# WS63 register map
File version: 1.0
CPU: other r0p0, little endian, MPU, FPU, 3 interrupt priority bits
Registers are 32-bit, read-write, reset 0x0 unless marked. A register's access mark holds for its fields unless they carry their own. Offsets are from the block's base; [hi:lo] are bit positions; {n}, {i} and the like mark numbered series.

## EFUSE — eFuse controller (OTP, v151)
Base 0x44008000
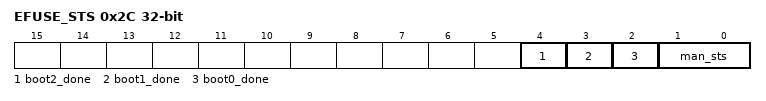
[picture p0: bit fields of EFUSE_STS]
0x2C EFUSE_STS — eFuse boot-done status register (base+0x2C). Read-only.
  [4] boot2_done ro — Boot2 done flag
  [3] boot1_done ro — Boot1 done flag
  [2] boot0_done ro — Boot0 done flag
  [1:0] man_sts ro — Manufacturing status
0x30 EFUSE_CTL_DATA — eFuse mode-select register (base+0x30). Write the 16-bit magic to arm an access: 0xA5A5 = program (write) mode, 0x5A5A = read mode.
  [15:0] efuse_wr_rd — Mode-select magic word (0xA5A5=write, 0x5A5A=read)
0x34 EFUSE_CLK_PERIOD — eFuse clock period register (base+0x34)
  [7:0] clk_period — Clock period in cycles (e.g. 0x29 @ 24MHz, 0x19 @ 40MHz)
0x3C EFUSE_AVDD_CTL — eFuse AVDD program-voltage switch (base+0x3C)
  [0] avdd_sw — AVDD switch: 1=enable program voltage, 0=disable
{0x800+4i} EFUSE_DATA[{i}] (i=0..127) — eFuse read/write data window (base+0x800), 128 words covering 256 bytes. Each 32-bit word packs two eFuse bytes: even byte address in [7:0], odd in [15:8]. Word index = byte_addr/2.
  [15:0] data — Two packed eFuse bytes (low byte=[7:0], high byte=[15:8])

## SYS_CTL0 — System Control 0 - reset status, clock control, PLL config
Base 0x40000000
0x08 RESET_COUNT
  [31:0] reset_count ro — Reset count value
0x14 HW_CTL — Hardware control register
  [0] refclk_freq_status ro — REFCLK frequency status: 0=40MHz; 1=24MHz
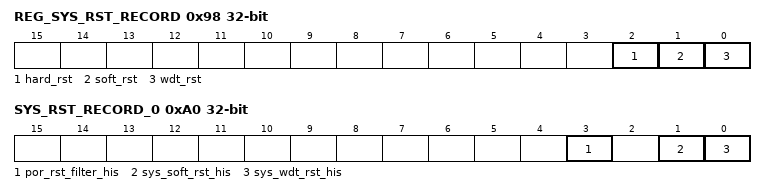
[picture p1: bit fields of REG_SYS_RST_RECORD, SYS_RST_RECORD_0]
0x98 REG_SYS_RST_RECORD — System reset record register
  [2] hard_rst — Hardware reset record
  [1] soft_rst — Software reset record
  [0] wdt_rst — Watchdog reset record
0xA0 SYS_RST_RECORD_0 — System reset history record 0
  [3] por_rst_filter_his ro — POR reset filter history
  [1] sys_soft_rst_his ro — Software reset history
  [0] sys_wdt_rst_his ro — WDT reset history
0xA4 SYS_DIAG_CLR_1 — System diagnostic clear 1
  [31:0] sys_diag_clr wo — Write to clear reset history bits

## GLB_CTL_M — Main core global control - BCPU/MCPU reset status, chip reset, AON CRG
Base 0x40002000
0x30 BCPU_RESET_STS — BCPU reset status register
  [31:0] bcpu_reset_sts ro — BCPU reset status
0x34 MCPU_RESET_STS — MCPU reset status register
  [31:0] mcpu_reset_sts ro — MCPU reset status
0x3C RESET_STS_CLEAR — Reset status clear register
  [31:0] rst_sts_clear wo — Write 0xFF to clear all reset status bits
0x100 AON_CRG_CKEN_CTL — AON CRG clock enable control
  [4] wdt_gate — WDT clock gate control at bit[4]
0x110 CHIP_RESET — Chip reset control register
  [2] chip_reset_en — Chip reset enable: 1=assert chip reset
0x110 AON_SOFT_RST_CTL — AON soft reset control
  [1] wdt_soft_rst — WDT soft reset at bit[1]

## SPACC — Security accelerator - AES/SM4/LEA/TDES symmetric crypto, HASH/HMAC
Base 0x44100000
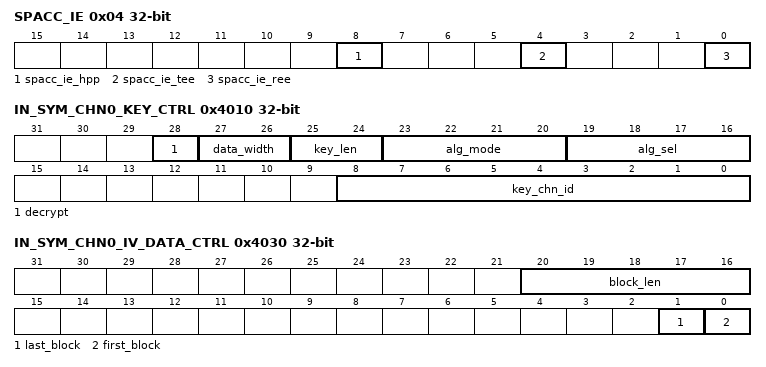
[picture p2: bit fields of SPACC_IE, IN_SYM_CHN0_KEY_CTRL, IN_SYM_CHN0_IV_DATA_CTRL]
0x04 SPACC_IE — SPACC interrupt enable
  [8] spacc_ie_hpp — HPP interrupt enable
  [4] spacc_ie_tee — TEE interrupt enable
  [0] spacc_ie_ree — REE interrupt enable
0x08 SPACC_INT_RAW_SYM_CLR_FINISH — Sym clear finish raw interrupt
  [15:0] raw_sym_clr_finish_int ro — Raw interrupt for sym clear finish
0x20 SPACC_SYM_CHN_LOCK — Sym channel lock register
  [31:0] sym_chn_lock — Symmetric channel lock status
0x40 SPACC_HASH_CHN_LOCK — Hash channel lock register
  [31:0] hash_chn_lock — Hash channel lock status
0x60 SPACC_SYM_CHN_CLEAR_REQ — Sym channel clear request
  [31:0] sym_chn_clear_req wo — Clear request for symmetric channels
0x68 SPACC_HASH_CHN_CLEAR_REQ — Hash channel clear request
  [31:0] hash_chn_clear_req wo — Clear request for hash channels
0x200 SPACC_BUS_ERR — Bus error register
  [31:0] bus_err ro — Bus error status
0x4000 IN_SYM_CHN0_CTRL — Sym channel 0 control register (no-DMA mode)
  [31] sym_chn0_req wo — Channel 0 start request
0x4004 IN_SYM_CHN0_SPECIAL_CTRL — Sym channel 0 special control
  [0] sym_chn0_odd_even — Odd/even control for TDES
0x4010 IN_SYM_CHN0_KEY_CTRL — Sym channel 0 key control (no-DMA mode)
  [28] decrypt — Decrypt: 0=encrypt; 1=decrypt
  [27:26] data_width — Data width: 0=128bit; 1=64bit; 2=32bit
    0=Width128 (128-bit data path); 1=Width64 (64-bit data path); 2=Width32 (32-bit data path)
  [25:24] key_len — Key length: 0=128bit; 1=192bit; 2=256bit
    0=Key128 (128-bit key); 1=Key192 (192-bit key); 2=Key256 (256-bit key)
  [23:20] alg_mode — Mode: 1=ECB; 3=CBC; 6=CTR; 0xA=GCM; 0xC=CMAC
    1=ECB (Electronic Codebook); 3=CBC (Cipher Block Chaining); 6=CTR (Counter mode); 7=OFB (Output Feedback); 8=CFB (Cipher Feedback); 9=CCM (CCM authenticated encryption); 10=GCM (Galois/Counter Mode); 11=GCTR (GCM CTR only); 12=CMAC (Cipher-based MAC)
  [19:16] alg_sel — Algorithm: 2=AES; 4=LEA; 5=SM4; 6=GHASH; 7=TDES
    2=AES (AES algorithm); 4=LEA (LEA (Lightweight Encryption Algorithm)); 5=SM4 (SM4 (Chinese national standard)); 6=GHASH (GHASH (GCM authentication)); 7=TDES (Triple DES)
  [8:0] key_chn_id — Key channel ID
0x4030 IN_SYM_CHN0_IV_DATA_CTRL — Sym channel 0 IV/data control (register mode)
  [20:16] block_len — Block length (in bytes)
  [1] last_block — Last block flag
  [0] first_block — First block flag
0x4040 IN_SYM_CHN0_IV0 — Sym channel 0 IV word 0 (register mode)
  [31:0] iv0 — IV[31:0]
{0x4040+4i} IN_SYM_CHN0_IV{i} (i=1..3) — Sym channel 0 IV word {i}
  [31:0] iv{i} — IV[{32i+31}:{32i}]
0x4050 IN_SYM_CHN0_DATA0 — Sym channel 0 data word 0 (register mode)
  [31:0] data0 — Input data[31:0]
0x8610 SYM_CHANN_RAW_INT — Sym channel raw interrupt status
  [15:0] sym_chann_raw_int ro — Raw interrupt per channel [15:0]
